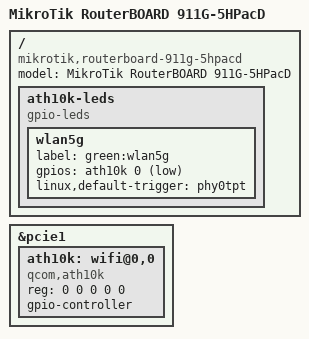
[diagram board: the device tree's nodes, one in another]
// SPDX-License-Identifier: GPL-2.0-or-later OR MIT

#include "qca9558_mikrotik_routerboard-92x.dtsi"

/ {
	compatible = "mikrotik,routerboard-911g-5hpacd", "qca,qca9558";
	model = "MikroTik RouterBOARD 911G-5HPacD";

	ath10k-leds {
		compatible = "gpio-leds";

		wlan5g {
			label = "green:wlan5g";
			gpios = <&ath10k 0 GPIO_ACTIVE_LOW>;
			linux,default-trigger = "phy0tpt";
		};
	};
};

&pcie1 {
	status = "okay";

	ath10k: wifi@0,0 {
		compatible = "qcom,ath10k";
		reg = <0 0 0 0 0>;
		#gpio-cells = <2>;
		gpio-controller;
	};
};
